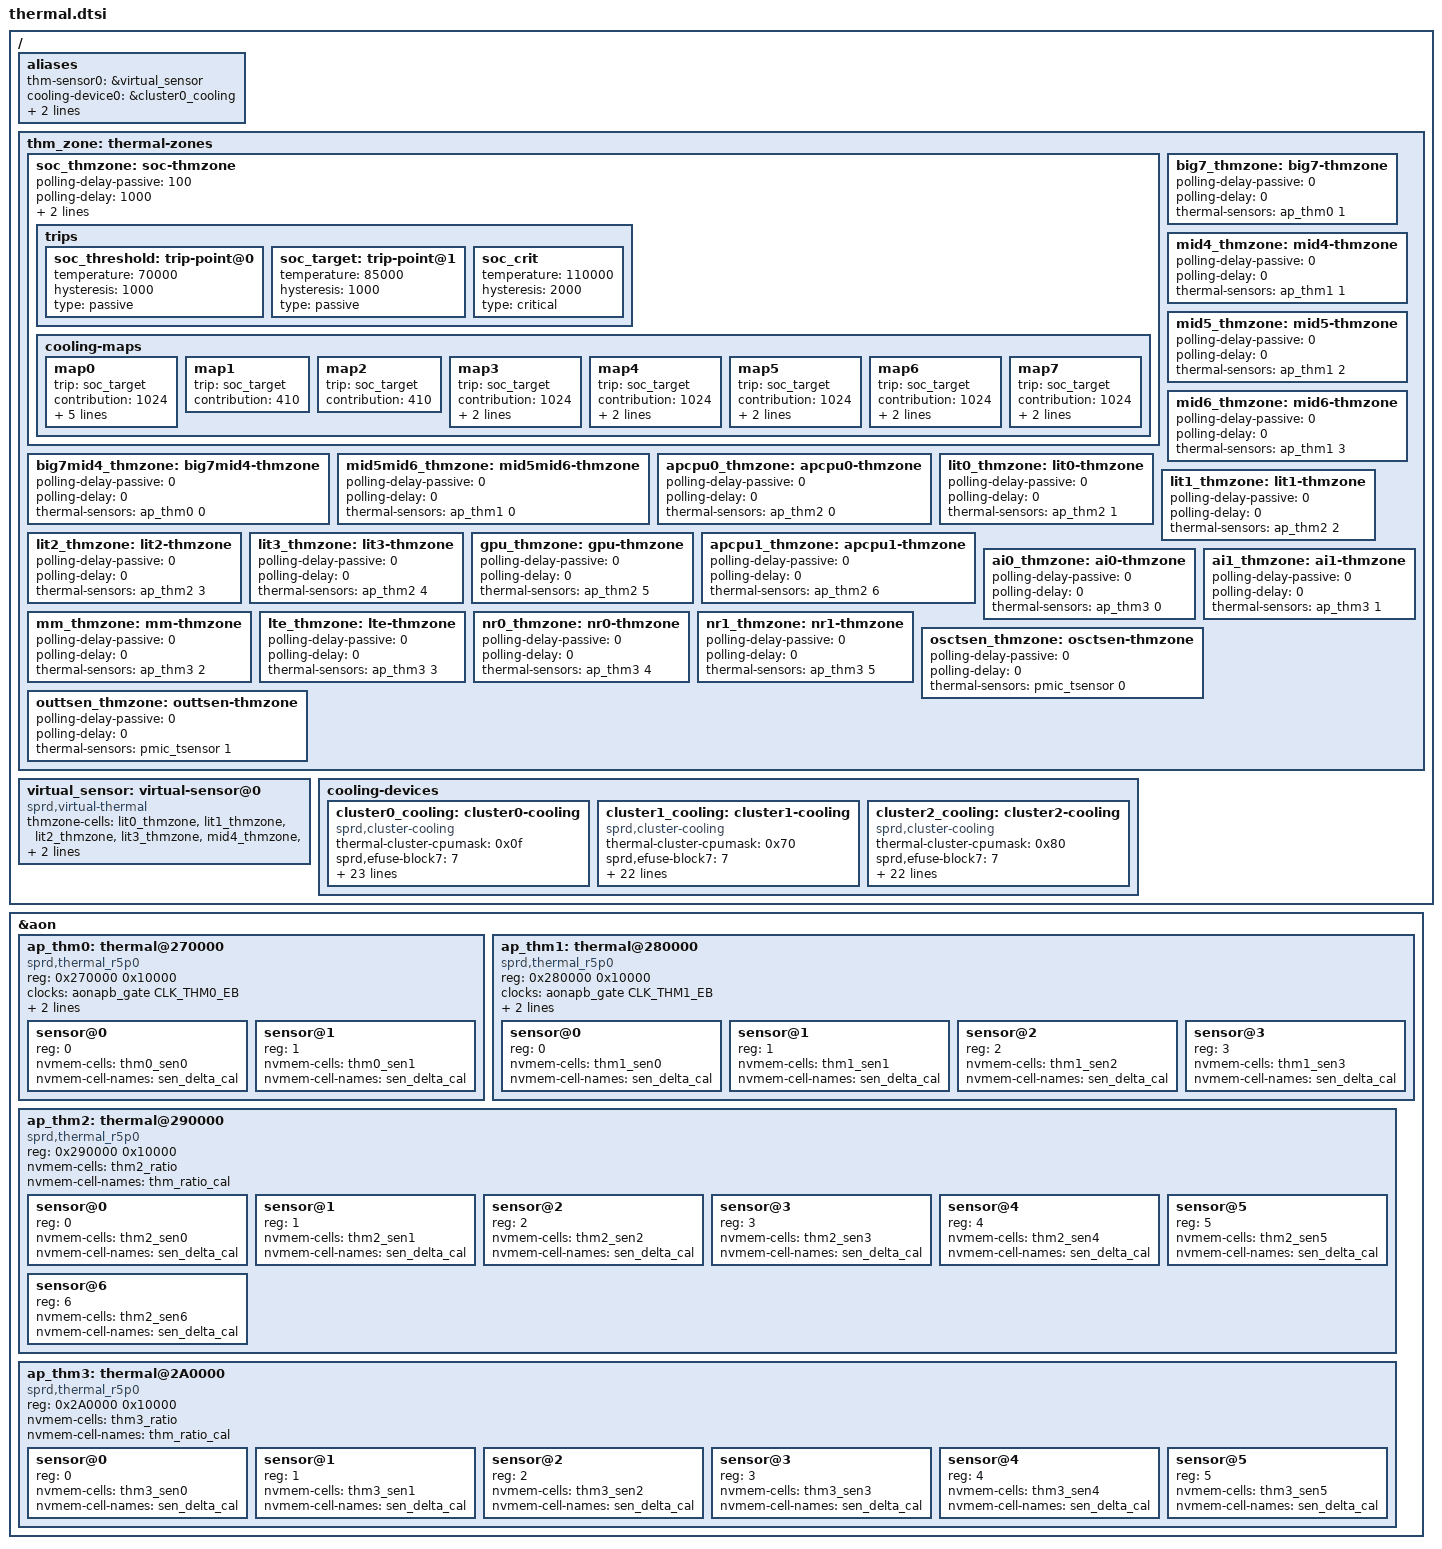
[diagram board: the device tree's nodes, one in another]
// SPDX-License-Identifier: (GPL-2.0+ OR MIT)
/*
 * Unisoc THERMAL dts file
 *
 * Copyright (C) 2020, Unisoc Inc.
 *
 */

#include <dt-bindings/thermal/thermal.h>

&aon {
	ap_thm0: thermal@270000 {
		compatible = "sprd,thermal_r5p0";
		reg = <0x270000 0x10000>;
		clock-names = "enable";
		clocks = <&aonapb_gate CLK_THM0_EB>;
		#thermal-sensor-cells = <1>;
		nvmem-cells = <&thm0_ratio>;
		nvmem-cell-names = "thm_ratio_cal";
		#address-cells = <1>;
		#size-cells = <0>;

		sensor@0 {
			reg = <0>;
			nvmem-cells = <&thm0_sen0>;
			nvmem-cell-names = "sen_delta_cal";
		};

		sensor@1 {
			reg = <1>;
			nvmem-cells = <&thm0_sen1>;
			nvmem-cell-names = "sen_delta_cal";
		};
	};

	ap_thm1: thermal@280000 {
		compatible = "sprd,thermal_r5p0";
		reg = <0x280000 0x10000>;
		clock-names = "enable";
		clocks = <&aonapb_gate CLK_THM1_EB>;
		#thermal-sensor-cells = <1>;
		nvmem-cells = <&thm1_ratio>;
		nvmem-cell-names = "thm_ratio_cal";
		#address-cells = <1>;
		#size-cells = <0>;

		sensor@0 {
			reg = <0>;
			nvmem-cells = <&thm1_sen0>;
			nvmem-cell-names = "sen_delta_cal";
		};

		sensor@1 {
			reg = <1>;
			nvmem-cells = <&thm1_sen1>;
			nvmem-cell-names = "sen_delta_cal";
		};

		sensor@2 {
			reg = <2>;
			nvmem-cells = <&thm1_sen2>;
			nvmem-cell-names = "sen_delta_cal";
		 };

		sensor@3 {
			reg = <3>;
			nvmem-cells = <&thm1_sen3>;
			nvmem-cell-names = "sen_delta_cal";
		};
	};

	ap_thm2: thermal@290000 {
		compatible = "sprd,thermal_r5p0";
		reg = <0x290000 0x10000>;
		clock-names = "enable";
//		clocks = <&aonapb_gate CLK_THM2_EB>;
		#thermal-sensor-cells = <1>;
		nvmem-cells = <&thm2_ratio>;
		nvmem-cell-names = "thm_ratio_cal";
		#address-cells = <1>;
		#size-cells = <0>;

		sensor@0 {
			reg = <0>;
			nvmem-cells = <&thm2_sen0>;
			nvmem-cell-names = "sen_delta_cal";
		};

		sensor@1 {
			reg = <1>;
			nvmem-cells = <&thm2_sen1>;
			nvmem-cell-names = "sen_delta_cal";
		};

		sensor@2 {
			reg = <2>;
			nvmem-cells = <&thm2_sen2>;
			nvmem-cell-names = "sen_delta_cal";
		};

		sensor@3 {
			reg = <3>;
			nvmem-cells = <&thm2_sen3>;
			nvmem-cell-names = "sen_delta_cal";
		};

		sensor@4 {
			reg = <4>;
			nvmem-cells = <&thm2_sen4>;
			nvmem-cell-names = "sen_delta_cal";
		};

		sensor@5 {
			reg = <5>;
			nvmem-cells = <&thm2_sen5>;
			nvmem-cell-names = "sen_delta_cal";
		};

		sensor@6 {
			reg = <6>;
			nvmem-cells = <&thm2_sen6>;
			nvmem-cell-names = "sen_delta_cal";
		};
	};

	ap_thm3: thermal@2A0000 {
		compatible = "sprd,thermal_r5p0";
		reg = <0x2A0000 0x10000>;
		clock-names = "enable";
//		clocks = <&aonapb_gate CLK_THM3_EB>;
		#thermal-sensor-cells = <1>;
		nvmem-cells = <&thm3_ratio>;
		nvmem-cell-names = "thm_ratio_cal";
		#address-cells = <1>;
		#size-cells = <0>;

		sensor@0 {
			reg = <0>;
			nvmem-cells = <&thm3_sen0>;
			nvmem-cell-names = "sen_delta_cal";
		};

		sensor@1 {
			reg = <1>;
			nvmem-cells = <&thm3_sen1>;
			nvmem-cell-names = "sen_delta_cal";
		};

		sensor@2 {
			reg = <2>;
			nvmem-cells = <&thm3_sen2>;
			nvmem-cell-names = "sen_delta_cal";
		};

		sensor@3 {
			reg = <3>;
			nvmem-cells = <&thm3_sen3>;
			nvmem-cell-names = "sen_delta_cal";
		};

		sensor@4 {
			reg = <4>;
			nvmem-cells = <&thm3_sen4>;
			nvmem-cell-names = "sen_delta_cal";
		};

		sensor@5 {
			reg = <5>;
			nvmem-cells = <&thm3_sen5>;
			nvmem-cell-names = "sen_delta_cal";
		};
	};
};

/ {
	aliases {
		thm-sensor0 = &virtual_sensor;
		cooling-device0 = &cluster0_cooling;
		cooling-device1 = &cluster1_cooling;
		cooling-device2 = &cluster2_cooling;
	};

	thm_zone: thermal-zones {
		soc_thmzone: soc-thmzone {
			polling-delay-passive = <100>;
			polling-delay = <1000>;
			sustainable-power = <3000>;
			thermal-sensors = <&virtual_sensor  0>;
			trips {
				soc_threshold: trip-point@0 {
					temperature = <70000>;
					hysteresis = <1000>;
					type = "passive";
				};
				soc_target: trip-point@1 {
					temperature = <85000>;
					hysteresis = <1000>;
					type = "passive";
				};
				soc_crit: soc_crit {
					temperature = <110000>;
					hysteresis = <2000>;
					type = "critical";
				};
			};
			cooling-maps {
				map0 {
					trip = <&soc_target>;
					contribution = <1024>;
					cooling-device =
					<&CPU0 THERMAL_NO_LIMIT THERMAL_NO_LIMIT>,
					<&CPU1 THERMAL_NO_LIMIT THERMAL_NO_LIMIT>,
					<&CPU2 THERMAL_NO_LIMIT THERMAL_NO_LIMIT>,
					<&CPU3 THERMAL_NO_LIMIT THERMAL_NO_LIMIT>;
				};
				map1 {
					trip = <&soc_target>;
					contribution = <410>;
				};
				map2 {
					trip = <&soc_target>;
					contribution = <410>;
				};
				map3 {
					trip = <&soc_target>;
					contribution = <1024>;
					cooling-device =
					<&cluster0_cooling THERMAL_NO_LIMIT \
					THERMAL_NO_LIMIT>;
				};
				map4 {
					trip = <&soc_target>;
					contribution = <1024>;
					cooling-device =
					<&cluster1_cooling THERMAL_NO_LIMIT \
					THERMAL_NO_LIMIT>;
				};
				map5 {
					trip = <&soc_target>;
					contribution = <1024>;
					cooling-device =
					<&cluster2_cooling THERMAL_NO_LIMIT \
					THERMAL_NO_LIMIT>;
				};
				map6 {
					trip = <&soc_target>;
					contribution = <1024>;
					cooling-device =
					<&gpu THERMAL_NO_LIMIT \
					THERMAL_NO_LIMIT>;
				};
				map7 {
					trip = <&soc_target>;
					contribution = <1024>;
					cooling-device =
					<&npu_img THERMAL_NO_LIMIT \
					THERMAL_NO_LIMIT>;
				};
			};
		};

		big7mid4_thmzone: big7mid4-thmzone {
			polling-delay-passive = <0>;
			polling-delay = <0>;
			thermal-sensors = <&ap_thm0 0>;
		};

		big7_thmzone: big7-thmzone {
			polling-delay-passive = <0>;
			polling-delay = <0>;
			thermal-sensors = <&ap_thm0 1>;
		};

		mid5mid6_thmzone: mid5mid6-thmzone {
			polling-delay-passive = <0>;
			polling-delay = <0>;
			thermal-sensors = <&ap_thm1 0>;
		};

		mid4_thmzone: mid4-thmzone {
			polling-delay-passive = <0>;
			polling-delay = <0>;
			thermal-sensors = <&ap_thm1 1>;
		};

		mid5_thmzone: mid5-thmzone {
			polling-delay-passive = <0>;
			polling-delay = <0>;
			thermal-sensors = <&ap_thm1 2>;
		};

		mid6_thmzone: mid6-thmzone {
			polling-delay-passive = <0>;
			polling-delay = <0>;
			thermal-sensors = <&ap_thm1 3>;
		};

		apcpu0_thmzone: apcpu0-thmzone {
			polling-delay-passive = <0>;
			polling-delay = <0>;
			thermal-sensors = <&ap_thm2 0>;
		};

		lit0_thmzone: lit0-thmzone {
			polling-delay-passive = <0>;
			polling-delay = <0>;
			thermal-sensors = <&ap_thm2 1>;
		};

		lit1_thmzone: lit1-thmzone {
			polling-delay-passive = <0>;
			polling-delay = <0>;
			thermal-sensors = <&ap_thm2 2>;
		};

		lit2_thmzone: lit2-thmzone {
			polling-delay-passive = <0>;
			polling-delay = <0>;
			thermal-sensors = <&ap_thm2 3>;
		};

		lit3_thmzone: lit3-thmzone {
			polling-delay-passive = <0>;
			polling-delay = <0>;
			thermal-sensors = <&ap_thm2 4>;
		};

		gpu_thmzone: gpu-thmzone {
			polling-delay-passive = <0>;
			polling-delay = <0>;
			thermal-sensors = <&ap_thm2 5>;
		};

		apcpu1_thmzone: apcpu1-thmzone {
			polling-delay-passive = <0>;
			polling-delay = <0>;
			thermal-sensors = <&ap_thm2 6>;
		};

		ai0_thmzone: ai0-thmzone {
			polling-delay-passive = <0>;
			polling-delay = <0>;
			thermal-sensors = <&ap_thm3 0>;
		};

		ai1_thmzone: ai1-thmzone {
			polling-delay-passive = <0>;
			polling-delay = <0>;
			thermal-sensors = <&ap_thm3 1>;
		};

		mm_thmzone: mm-thmzone {
			polling-delay-passive = <0>;
			polling-delay = <0>;
			thermal-sensors = <&ap_thm3 2>;
		};

		lte_thmzone: lte-thmzone {
			polling-delay-passive = <0>;
			polling-delay = <0>;
			thermal-sensors = <&ap_thm3 3>;
		};

		nr0_thmzone: nr0-thmzone {
			polling-delay-passive = <0>;
			polling-delay = <0>;
			thermal-sensors = <&ap_thm3 4>;
		};

		nr1_thmzone: nr1-thmzone {
			polling-delay-passive = <0>;
			polling-delay = <0>;
			thermal-sensors = <&ap_thm3 5>;
		};

		osctsen_thmzone: osctsen-thmzone {
			polling-delay-passive = <0>;
			polling-delay = <0>;
			thermal-sensors = <&pmic_tsensor 0>;
		};

		outtsen_thmzone: outtsen-thmzone {
			polling-delay-passive = <0>;
			polling-delay = <0>;
			thermal-sensors = <&pmic_tsensor 1>;
		};
	};

	virtual_sensor: virtual-sensor@0 {
		compatible = "sprd,virtual-thermal";
		#thermal-sensor-cells = <1>;
		thmzone-cells = <&lit0_thmzone>, <&lit1_thmzone>, <&lit2_thmzone>,
			<&lit3_thmzone>, <&mid4_thmzone>, <&mid5_thmzone>,
			<&mid6_thmzone>, <&big7_thmzone>, <&gpu_thmzone>,
			<&ai0_thmzone>, <&ai1_thmzone>;
	};

	cooling-devices {
		cluster0_cooling: cluster0-cooling {
			compatible = "sprd,cluster-cooling";
			#cooling-cells = <2>; /* min followed by max */
			thermal-cluster-cpumask = <0x0f>;
			sprd,efuse-block7 = <7>;
			sprd,efuse-block15 = <15>;
			/* core_leak =                             */
			/*(LIT_LEAK[4:0]+1) x 2mA x 0.85V x 18.69% */
			sprd,leak-core = <2 85 1869>;
			/* cluster_leak =                           */
			/* (LIT_LEAK[4:0]+1) x 2mA x 0.85V x 25.24% */
			sprd,leak-cluster = <2 85 2524>;
			/*core Tscale = aT^3 + bT^2 + cT +di   */
			sprd,core-temp-scale =
			/* a*10^7   b*10^7      c*10^7     d*10^7 */
			<  32      (-3740)      208490    (-1646820)>;
			/*core Vscale = eV^3 + fV^2 + gV + h */
			sprd,core-voltage-scale =
			/* e*10^2   f*10^2     g*10^2  h*10^2*/
			<  556     (-1125)      869      (-200)>;
			/*cluster Tscale = aT^3 + bT^2 + cT +di   */
			sprd,cluster-temp-scale =
			/* a*10^7   b*10^7      c*10^7     d*10^7 */
			<  21      (-1871)      110281    (-303179)>;
			/*cluster Vscale = eV^3 + fV^2 + gV + h */
			sprd,cluster-voltage-scale =
			/* e*10^2   f*10^2     g*10^2  h*10^2*/
			<  1543     (-3288)      2419      (-574)>;
			sprd,efuse-switch = <0>;
			sprd,hotplug-period = <10>;
			sprd,min-cpufreq = <614400>;
			sprd,min-cpunum = <1>;
			sprd,max-temp = <90000>;
			sprd,core-base = <2163>;
			sprd,cluster-base = <9406>;
			sprd,dynamic-core =
			/*Pdynperghz*10    Freq     Vbase  */
			< 774           1000     1000>;
			sprd,dynamic-cluster =
			/*Pdynperghz*10    Freq     Vbase  */
			< 1544           1000     1000>;
			sprd,cii-per-core-tp = <105000 100000 95000 90000>;
			sprd,cii-max-tp-core = <90000>;
		};

		cluster1_cooling: cluster1-cooling {
			compatible = "sprd,cluster-cooling";
			thermal-cluster-cpumask = <0x70>;
			#cooling-cells = <2>; /* min followed by max */
			sprd,efuse-block7 = <7>;
			sprd,efuse-block15 = <15>;
			/* core_leak =                             */
			/*(LIT_LEAK[4:0]+1) x 2mA x 0.85V x 18.69% */
			sprd,leak-core = <8 85 1984>;
			/* cluster_leak =                           */
			/* (LIT_LEAK[4:0]+1) x 2mA x 0.85V x 25.24% */
			sprd,leak-cluster = <8 85 2064>;
			/*core Tscale = aT^3 + bT^2 + cT +d  */
			sprd,core-temp-scale =
			/* a*10^7   b*10^7	c*10^7	   d*10^7*/
			<  29      (-3437)      197879    (-1480529)>;
			/* core  Vscale = eV^3 + fV^2 + gV + h */
			sprd,core-voltage-scale =
			/* e*10^2  f*10^2     g*10^2  h*10^2*/
			<  660     (-1350)      1028      (-238)>;
			/*cluster Tscale = aT^3 + bT^2 + cT +di   */
			sprd,cluster-temp-scale =
			/* a*10^7   b*10^7      c*10^7     d*10^7 */
			<  21      (-1871)      110281    (-303179)>;
			/*cluster Vscale = eV^3 + fV^2 + gV + h */
			sprd,cluster-voltage-scale =
			/* e*10^2   f*10^2     g*10^2  h*10^2*/
			<  1543     (-3288)      2419      (-574)>;
			sprd,efuse-switch = <0>;
			sprd,hotplug-period = <10>;
			sprd,min-cpufreq = <1228800>;
			sprd,min-cpunum = <0>;
			sprd,max-temp = <85000>;
			sprd,core-base = <13764>;
			sprd,cluster-base = <9406>;
			sprd,dynamic-core =
			/* Pdynperghz*10    Freq     Vbase */
			<  3602          1000     1000>;
			sprd,dynamic-cluster =
			/* Pdynperghz*10    Freq     Vbase */
			<  1544            1000     1000>;
			sprd,cii-per-core-tp = <85000 80000 75000 70000>;
			sprd,cii-max-tp-core = <75000>;
		};

		cluster2_cooling: cluster2-cooling {
			compatible = "sprd,cluster-cooling";
			thermal-cluster-cpumask = <0x80>;
			#cooling-cells = <2>; /* min followed by max */
			sprd,efuse-block7 = <7>;
			sprd,efuse-block15 = <15>;
			/* core_leak =                             */
			/*(LIT_LEAK[4:0]+1) x 2mA x 0.85V x 18.69% */
			sprd,leak-core = <8 85 1984>;
			/* cluster_leak =                           */
			/* (LIT_LEAK[4:0]+1) x 2mA x 0.85V x 25.24% */
			sprd,leak-cluster = <8 85 2064>;
			/*core Tscale = aT^3 + bT^2 + cT +d  */
			sprd,core-temp-scale =
			/* a*10^7   b*10^7	c*10^7	   d*10^7*/
			<  31      (-3318)      196102    (-1472368)>;
			/* core  Vscale = eV^3 + fV^2 + gV + h */
			sprd,core-voltage-scale =
			/* e*10^2  f*10^2     g*10^2  h*10^2*/
			<  556     (-1125)      869      (-200)>;
			/*cluster Tscale = aT^3 + bT^2 + cT +di   */
			sprd,cluster-temp-scale =
			/* a*10^7   b*10^7      c*10^7     d*10^7 */
			<  21      (-1871)      110281    (-303179)>;
			/*cluster Vscale = eV^3 + fV^2 + gV + h */
			sprd,cluster-voltage-scale =
			/* e*10^2   f*10^2     g*10^2  h*10^2*/
			<  1543     (-3288)      2419      (-574)>;
			sprd,efuse-switch = <0>;
			sprd,hotplug-period = <10>;
			sprd,min-cpufreq = <1228800>;
			sprd,min-cpunum = <0>;
			sprd,max-temp = <85000>;
			sprd,core-base = <16032>;
			sprd,cluster-base = <9406>;
			sprd,dynamic-core =
			/* Pdynperghz*10    Freq     Vbase */
			<  4479          1000     1000>;
			sprd,dynamic-cluster =
			/* Pdynperghz*10    Freq     Vbase */
			<  1544            1000     1000>;
			sprd,cii-per-core-tp = <85000 80000 75000 70000>;
			sprd,cii-max-tp-core = <75000>;
		};
	};
};
